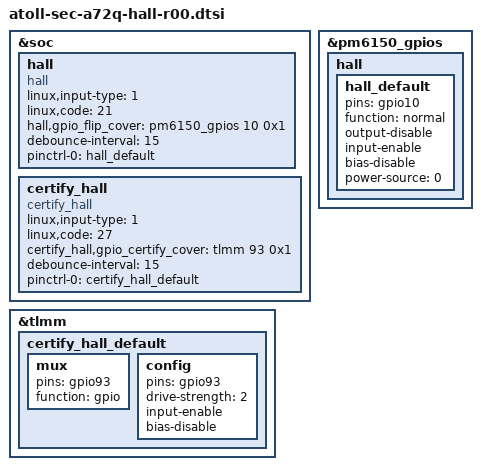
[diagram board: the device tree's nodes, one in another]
/* Copyright (c) 2016-2019, The Linux Foundation. All rights reserved.
 *
 * This program is free software; you can redistribute it and/or modify
 * it under the terms of the GNU General Public License version 2 and
 * only version 2 as published by the Free Software Foundation.
 *
 * This program is distributed in the hope that it will be useful,
 * but WITHOUT ANY WARRANTY; without even the implied warranty of
 * MERCHANTABILITY or FITNESS FOR A PARTICULAR PURPOSE.  See the
 * GNU General Public License for more details.
 */

&soc {
	hall {
		status = "okay";
		compatible = "hall";
		linux,input-type = <1>;
		linux,code = <21>;
		hall,gpio_flip_cover = <&pm6150_gpios 10 0x1>;
		debounce-interval = <15>;
		pinctrl-names = "default";
		pinctrl-0 = <&hall_default>;
	};

	certify_hall {
		status = "okay";
		compatible = "certify_hall";
		linux,input-type = <1>;
		linux,code = <27>;
		certify_hall,gpio_certify_cover = <&tlmm 93 0x1>;
		debounce-interval = <15>;
		pinctrl-names = "default";
		pinctrl-0 = <&certify_hall_default>;
	};
};

&pm6150_gpios {
	hall {
		hall_default: hall_default {
			pins = "gpio10";
			function = "normal";
			output-disable;
			input-enable;
			bias-disable;
			power-source = <0>;
		};
	};
};

&tlmm {
	certify_hall_default: certify_hall_default {
		mux {
			pins = "gpio93";
			function = "gpio";
		};
		config {
			pins = "gpio93";
			drive-strength = <2>;
			input-enable;
			bias-disable;
		};
	};
};

